# AM13E23219 register map
Vendor: Texas Instruments; File version: 1.0
CPU: CM33 r0p1, little endian, MPU, FPU, VTOR, 4 interrupt priority bits
Registers are 32-bit, read-write, reset 0x0 unless marked. A register's access mark holds for its fields unless they carry their own. Offsets are from the block's base; [hi:lo] are bit positions; {n}, {i} and the like mark numbered series.

## INPUTXBAR_FLAGS — INPUT_FLAG_XBAR module
Base 0x40490000
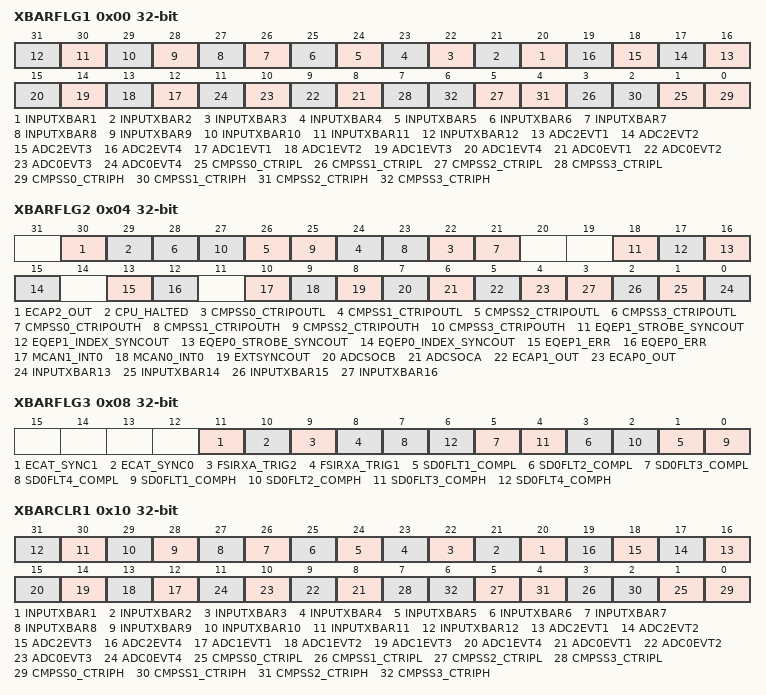
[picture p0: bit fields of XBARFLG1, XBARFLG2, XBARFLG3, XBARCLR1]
0x00 XBARFLG1 ro — X-Bar Input Flag Register 1
  [n+19] INPUTXBAR{n} (n=1..12) — Input Flag for INPUTXBAR{n} Signal
  [n+15] ADC2EVT{n} (n=1..4) — Input Flag for ADC2EVT{n} Signal
  [n+11] ADC1EVT{n} (n=1..4) — Input Flag for ADC1EVT{n} Signal
  [n+7] ADC0EVT{n} (n=1..4) — Input Flag for ADC0EVT{n} Signal
  [2n+1] CMPSS{n}_CTRIPL (n=0..3) — Input Flag for CMPSS{n}_CTRIPL Signal
  [2n] CMPSS{n}_CTRIPH (n=0..3) — Input Flag for CMPSS{n}_CTRIPH Signal
0x04 XBARFLG2 ro — X-Bar Input Flag Register 2
  [30] ECAP2_OUT — Input Flag for ECAP2_OUT Signal
  [29] CPU_HALTED — Input Flag for CPU_HALTED Signal
  [2n+22] CMPSS{n}_CTRIPOUTL (n=0..3) — Input Flag for CMPSS{n}_CTRIPOUTL Signal
  [2n+21] CMPSS{n}_CTRIPOUTH (n=0..3) — Input Flag for CMPSS{n}_CTRIPOUTH Signal
  [18] EQEP1_STROBE_SYNCOUT — Input Flag for EQEP1_STROBE_SYNCOUT Signal
  [17] EQEP1_INDEX_SYNCOUT — Input Flag for EQEP1_INDEX_SYNCOUT Signal
  [16] EQEP0_STROBE_SYNCOUT — Input Flag for EQEP0_STROBE_SYNCOUT Signal
  [15] EQEP0_INDEX_SYNCOUT — Input Flag for EQEP0_INDEX_SYNCOUT Signal
  [13] EQEP1_ERR — Input Flag for EQEP1_ERR Signal
  [12] EQEP0_ERR — Input Flag for EQEP0_ERR Signal
  [10] MCAN1_INT0 — Input Flag for MCAN1_INT0 Signal
  [9] MCAN0_INT0 — Input Flag for MCAN0_INT0 Signal
  [8] EXTSYNCOUT — Input Flag for EXTSYNCOUT Signal
  [7] ADCSOCB — Input Flag for ADCSOCB Signal
  [6] ADCSOCA — Input Flag for ADCSOCA Signal
  [5] ECAP1_OUT — Input Flag for ECAP1_OUT Signal
  [4] ECAP0_OUT — Input Flag for ECAP0_OUT Signal
  [n-13] INPUTXBAR{n} (n=13..16) — Input Flag for INPUTXBAR{n} Signal
0x08 XBARFLG3 ro — X-Bar Input Flag Register 3
  [11] ECAT_SYNC1 — Input Flag for ECAT_SYNC1 Signal
  [10] ECAT_SYNC0 — Input Flag for ECAT_SYNC0 Signal
  [9] FSIRXA_TRIG2 — Input Flag for FSIRXA_TRIG2 Signal
  [8] FSIRXA_TRIG1 — Input Flag for FSIRXA_TRIG1 Signal
  [2n-1] SD0FLT{n}_COMPL (n=1..4) — Input Flag for SD0FLT{n}_COMPL Signal
  [2n-2] SD0FLT{n}_COMPH (n=1..4) — Input Flag for SD0FLT{n}_COMPH Signal
0x10 XBARCLR1 — X-Bar Input Flag Clear Register 1
  [n+19] INPUTXBAR{n} (n=1..12) — Input Flag Clear for INPUTXBAR{n} Signal
  [n+15] ADC2EVT{n} (n=1..4) — Input Flag Clear for ADC2EVT{n} Signal
  [n+11] ADC1EVT{n} (n=1..4) — Input Flag Clear for ADC1EVT{n} Signal
  [n+7] ADC0EVT{n} (n=1..4) — Input Flag Clear for ADC0EVT{n} Signal
  [2n+1] CMPSS{n}_CTRIPL (n=0..3) — Input Flag Clear for CMPSS{n}_CTRIPL Signal
  [2n] CMPSS{n}_CTRIPH (n=0..3) — Input Flag Clear for CMPSS{n}_CTRIPH Signal
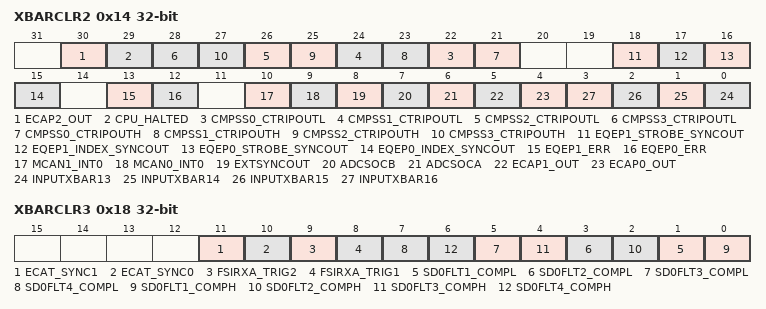
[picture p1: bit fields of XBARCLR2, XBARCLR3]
0x14 XBARCLR2 — X-Bar Input Flag Clear Register 2
  [30] ECAP2_OUT — Input Flag Clear for ECAP2_OUT Signal
  [29] CPU_HALTED — Input Flag Clear for CPU_HALTED Signal
  [2n+22] CMPSS{n}_CTRIPOUTL (n=0..3) — Input Flag Clear for CMPSS{n}_CTRIPOUTL Signal
  [2n+21] CMPSS{n}_CTRIPOUTH (n=0..3) — Input Flag Clear for CMPSS{n}_CTRIPOUTH Signal
  [18] EQEP1_STROBE_SYNCOUT — Input Flag Clear for EQEP1_STROBE_SYNCOUT Signal
  [17] EQEP1_INDEX_SYNCOUT — Input Flag Clear for EQEP1_INDEX_SYNCOUT Signal
  [16] EQEP0_STROBE_SYNCOUT — Input Flag Clear for EQEP0_STROBE_SYNCOUT Signal
  [15] EQEP0_INDEX_SYNCOUT — Input Flag Clear for EQEP0_INDEX_SYNCOUT Signal
  [13] EQEP1_ERR — Input Flag Clear for EQEP1_ERR Signal
  [12] EQEP0_ERR — Input Flag Clear for EQEP0_ERR Signal
  [10] MCAN1_INT0 — Input Flag Clear for MCAN1_INT0 Signal
  [9] MCAN0_INT0 — Input Flag Clear for MCAN0_INT0 Signal
  [8] EXTSYNCOUT — Input Flag Clear for EXTSYNCOUT Signal
  [7] ADCSOCB — Input Flag Clear for ADCSOCB Signal
  [6] ADCSOCA — Input Flag Clear for ADCSOCA Signal
  [5] ECAP1_OUT — Input Flag Clear for ECAP1_OUT Signal
  [4] ECAP0_OUT — Input Flag Clear for ECAP0_OUT Signal
  [n-13] INPUTXBAR{n} (n=13..16) — Input Flag Clear for INPUTXBAR{n} Signal
0x18 XBARCLR3 — X-Bar Input Flag Clear Register 3
  [11] ECAT_SYNC1 — Input Flag Clear for ECAT_SYNC1 Signal
  [10] ECAT_SYNC0 — Input Flag Clear for ECAT_SYNC0 Signal
  [9] FSIRXA_TRIG2 — Input Flag Clear for FSIRXA_TRIG2 Signal
  [8] FSIRXA_TRIG1 — Input Flag Clear for FSIRXA_TRIG1 Signal
  [2n-1] SD0FLT{n}_COMPL (n=1..4) — Input Flag Clear for SD0FLT{n}_COMPL Signal
  [2n-2] SD0FLT{n}_COMPH (n=1..4) — Input Flag Clear for SD0FLT{n}_COMPH Signal
